# MK22F12810 register map
Vendor: Freescale Semiconductor, Inc.; Series: Kinetis_K; File version: 1.6
CPU: CM4 r0p1, little endian, no MPU, FPU, VTOR, 4 interrupt priority bits
Registers are 32-bit, read-write, reset 0x0 unless marked. A register's access mark holds for its fields unless they carry their own. Offsets are from the block's base; [hi:lo] are bit positions; {n}, {i} and the like mark numbered series.

## USB0 — Universal Serial Bus, OTG Capable Controller
Base 0x40072000; register names take the prefix USB0_
0x00 PERID 8-bit ro reset 0x4 — Peripheral ID register
  [5:0] ID — Peripheral Identification
0x04 IDCOMP 8-bit ro reset 0xFB — Peripheral ID Complement register
  [5:0] NID
0x08 REV 8-bit ro reset 0x33 — Peripheral Revision register
  [7:0] REV — Revision
0x0C ADDINFO 8-bit ro reset 0x1 — Peripheral Additional Info register
  [0] IEHOST
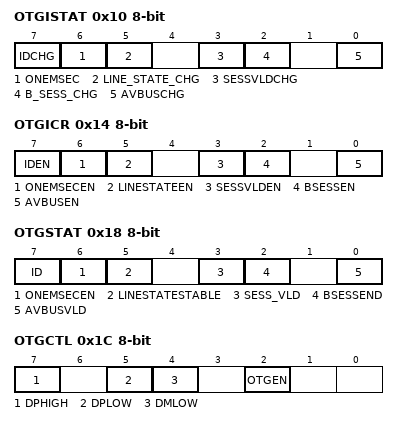
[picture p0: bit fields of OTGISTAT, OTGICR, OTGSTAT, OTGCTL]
0x10 OTGISTAT 8-bit — OTG Interrupt Status register
  [7] IDCHG, [6] ONEMSEC, [5] LINE_STATE_CHG, [3] SESSVLDCHG, [2] B_SESS_CHG, [0] AVBUSCHG
0x14 OTGICR 8-bit — OTG Interrupt Control register
  [7] IDEN — ID Interrupt Enable
    0=The ID interrupt is disabled; 1=The ID interrupt is enabled
  [6] ONEMSECEN — One Millisecond Interrupt Enable
    0=Diables the 1ms timer interrupt; 1=Enables the 1ms timer interrupt
  [5] LINESTATEEN — Line State Change Interrupt Enable
    0=Disables the LINE_STAT_CHG interrupt; 1=Enables the LINE_STAT_CHG interrupt
  [3] SESSVLDEN — Session Valid Interrupt Enable
    0=Disables the SESSVLDCHG interrupt; 1=Enables the SESSVLDCHG interrupt
  [2] BSESSEN — B Session END Interrupt Enable
    0=Disables the B_SESS_CHG interrupt; 1=Enables the B_SESS_CHG interrupt
  [0] AVBUSEN — A VBUS Valid Interrupt Enable
    0=Disables the AVBUSCHG interrupt; 1=Enables the AVBUSCHG interrupt
0x18 OTGSTAT 8-bit — OTG Status register
  [7] ID
    0=Indicates a Type A cable is plugged into the USB connector; 1=Indicates no cable is attached or a Type B cable is plugged into the USB connector
  [6] ONEMSECEN
  [5] LINESTATESTABLE
    0=The LINE_STAT_CHG bit is not yet stable; 1=The LINE_STAT_CHG bit has been debounced and is stable
  [3] SESS_VLD — Session Valid
    0=The VBUS voltage is below the B session valid threshold; 1=The VBUS voltage is above the B session valid threshold
  [2] BSESSEND — B Session End
    0=The VBUS voltage is above the B session end threshold; 1=The VBUS voltage is below the B session end threshold
  [0] AVBUSVLD — A VBUS Valid
    0=The VBUS voltage is below the A VBUS Valid threshold; 1=The VBUS voltage is above the A VBUS Valid threshold
0x1C OTGCTL 8-bit — OTG Control register
  [7] DPHIGH — D+ Data Line pullup resistor enable
    0=D+ pullup resistor is not enabled; 1=D+ pullup resistor is enabled
  [5] DPLOW — D+ Data Line pull-down resistor enable
    0=D+ pulldown resistor is not enabled; 1=D+ pulldown resistor is enabled
  [4] DMLOW — D- Data Line pull-down resistor enable
    0=D- pulldown resistor is not enabled; 1=D- pulldown resistor is enabled
  [2] OTGEN — On-The-Go pullup/pulldown resistor enable
    0=If USB_EN is 1 and HOST_MODE is 0 in the Control Register (CTL), then the D+ Data Line pull-up resistors are enabled. If HOST_MODE is 1 the D+ and D- Data Line pull-down resistors are engaged.; 1=The pull-up and pull-down controls in this register are used
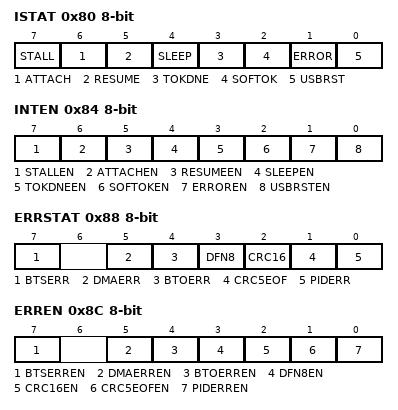
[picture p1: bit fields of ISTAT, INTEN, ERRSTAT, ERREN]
0x80 ISTAT 8-bit — Interrupt Status register
  [7] STALL — Stall Interrupt
  [6] ATTACH — Attach Interrupt
    0=No Attach is detected since the last time the ATTACH bit was cleared; 1=A peripheral is now present and must be configured (a stable non-SE0 state is detected for more than 2.5 us)
  [5] RESUME
  [4] SLEEP
  [3] TOKDNE
  [2] SOFTOK
  [1] ERROR
  [0] USBRST
0x84 INTEN 8-bit — Interrupt Enable register
  [7] STALLEN — STALL Interrupt Enable
    0=Diasbles the STALL interrupt; 1=Enables the STALL interrupt
  [6] ATTACHEN — ATTACH Interrupt Enable
    0=Disables the ATTACH interrupt; 1=Enables the ATTACH interrupt
  [5] RESUMEEN — RESUME Interrupt Enable
    0=Disables the RESUME interrupt; 1=Enables the RESUME interrupt
  [4] SLEEPEN — SLEEP Interrupt Enable
    0=Disables the SLEEP interrupt; 1=Enables the SLEEP interrupt
  [3] TOKDNEEN — TOKDNE Interrupt Enable
    0=Disables the TOKDNE interrupt; 1=Enables the TOKDNE interrupt
  [2] SOFTOKEN — SOFTOK Interrupt Enable
    0=Disbles the SOFTOK interrupt; 1=Enables the SOFTOK interrupt
  [1] ERROREN — ERROR Interrupt Enable
    0=Disables the ERROR interrupt; 1=Enables the ERROR interrupt
  [0] USBRSTEN — USBRST Interrupt Enable
    0=Disables the USBRST interrupt; 1=Enables the USBRST interrupt
0x88 ERRSTAT 8-bit — Error Interrupt Status register
  [7] BTSERR, [5] DMAERR, [4] BTOERR, [3] DFN8, [2] CRC16, [1] CRC5EOF, [0] PIDERR
0x8C ERREN 8-bit — Error Interrupt Enable register
  [7] BTSERREN — BTSERR Interrupt Enable
    0=Disables the BTSERR interrupt; 1=Enables the BTSERR interrupt
  [5] DMAERREN — DMAERR Interrupt Enable
    0=Disables the DMAERR interrupt; 1=Enables the DMAERR interrupt
  [4] BTOERREN — BTOERR Interrupt Enable
    0=Disables the BTOERR interrupt; 1=Enables the BTOERR interrupt
  [3] DFN8EN — DFN8 Interrupt Enable
    0=Disables the DFN8 interrupt; 1=Enables the DFN8 interrupt
  [2] CRC16EN — CRC16 Interrupt Enable
    0=Disables the CRC16 interrupt; 1=Enables the CRC16 interrupt
  [1] CRC5EOFEN — CRC5/EOF Interrupt Enable
    0=Disables the CRC5/EOF interrupt; 1=Enables the CRC5/EOF interrupt
  [0] PIDERREN — PIDERR Interrupt Enable
    0=Disables the PIDERR interrupt; 1=Enters the PIDERR interrupt
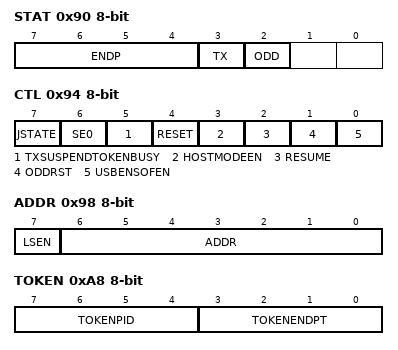
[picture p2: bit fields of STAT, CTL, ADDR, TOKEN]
0x90 STAT 8-bit ro — Status register
  [7:4] ENDP
  [3] TX — Transmit Indicator
    0=The most recent transaction was a receive operation; 1=The most recent transaction was a transmit operation
  [2] ODD
0x94 CTL 8-bit — Control register
  [7] JSTATE — Live USB differential receiver JSTATE signal
  [6] SE0 — Live USB Single Ended Zero signal
  [5] TXSUSPENDTOKENBUSY
  [4] RESET
  [3] HOSTMODEEN
  [2] RESUME
  [1] ODDRST
  [0] USBENSOFEN — USB Enable
    0=Disables the USB Module; 1=Enables the USB Module
0x98 ADDR 8-bit — Address register
  [7] LSEN — Low Speed Enable bit
  [6:0] ADDR — USB Address
0x9C BDTPAGE1 8-bit — BDT Page register 1
  [7:1] BDTBA
0xA0 FRMNUML 8-bit — Frame Number register Low
  [7:0] FRM
0xA4 FRMNUMH 8-bit — Frame Number register High
  [2:0] FRM
0xA8 TOKEN 8-bit
  [7:4] TOKENPID
    1=OUT Token. USB Module performs an OUT (TX) transaction.; 9=IN Token. USB Module performs an In (RX) transaction.; 13=SETUP Token. USB Module performs a SETUP (TX) transaction
  [3:0] TOKENENDPT
0xAC SOFTHLD 8-bit — SOF Threshold register
  [7:0] CNT
0xB0 BDTPAGE2 8-bit — BDT Page Register 2
  [7:0] BDTBA
0xB4 BDTPAGE3 8-bit — BDT Page Register 3
  [7:0] BDTBA
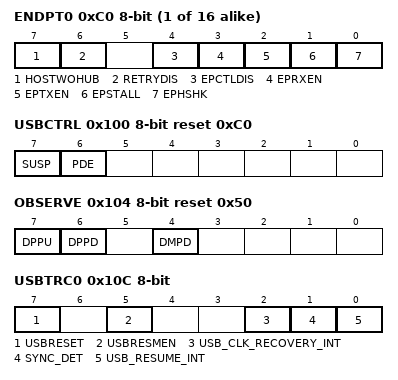
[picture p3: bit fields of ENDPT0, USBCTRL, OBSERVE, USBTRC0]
{0xC0+4i} ENDPT{i} (i=0..15) 8-bit — Endpoint Control register
  [7] HOSTWOHUB
    0=Low-speed device connected to Host through a hub. PRE_PID will be generated as required.; 1=Low-speed device directly connected. No hub, or no low-speed device attached.
  [6] RETRYDIS
  [4] EPCTLDIS
  [3] EPRXEN
  [2] EPTXEN
  [1] EPSTALL
  [0] EPHSHK
0x100 USBCTRL 8-bit reset 0xC0 — USB Control register
  [7] SUSP
    0=USB transceiver is not in suspend state; 1=USB transceiver is in suspend state
  [6] PDE
    0=Weak pulldowns are disabled on D+ and D-; 1=Weak pulldowns are enabled on D+ and D-
0x104 OBSERVE 8-bit ro reset 0x50 — USB OTG Observe register
  [7] DPPU
    0=D+ pullup disabled; 1=D+ pullup enabled
  [6] DPPD
    0=D+ pulldown disabled; 1=D+ pulldown enabled
  [4] DMPD
    0=D- pulldown disabled; 1=D- pulldown enabled
0x108 CONTROL 8-bit — USB OTG Control register
  [4] DPPULLUPNONOTG
    0=DP Pullup in non-OTG device mode is not enabled; 1=DP Pullup in non-OTG device mode is enabled
0x10C USBTRC0 8-bit — USB Transceiver Control register 0
  [7] USBRESET wo
    0=Normal USB module operation; 1=Returns the USB module to its reset state
  [5] USBRESMEN — Asynchronous Resume Interrupt Enable
    0=USB asynchronous wakeup from suspend mode disabled; 1=USB asynchronous wakeup from suspend mode enabled. The asynchronous resume interrupt differs from the synchronous resume interrupt in that it asynchronously detects K-state using the unfiltered state of the D+ and D- pins. This interrupt should only be enabled when the Transceiver is suspended.
  [2] USB_CLK_RECOVERY_INT ro — Combined USB Clock Recovery interrupt status
  [1] SYNC_DET ro — Synchronous USB Interrupt Detect
    0=Synchronous interrupt has not been detected; 1=Synchronous interrupt has been detected
  [0] USB_RESUME_INT ro — USB Asynchronous Interrupt
    0=No interrupt was generated; 1=Interrupt was generated because of the USB asynchronous interrupt
0x114 USBFRMADJUST 8-bit — Frame Adjust Register
  [7:0] ADJ — Frame Adjustment
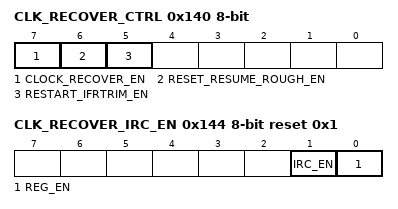
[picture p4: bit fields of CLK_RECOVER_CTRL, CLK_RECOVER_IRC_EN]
0x140 CLK_RECOVER_CTRL 8-bit — USB Clock recovery control
  [7] CLOCK_RECOVER_EN — Crystal-less USB enable
    0=Disable clock recovery block (default); 1=Enable clock recovery block
  [6] RESET_RESUME_ROUGH_EN — Reset/resume to rough phase enable
    0=Always works in tracking phase after the 1st time rough to track transition (default); 1=Go back to rough stage whenever bus reset or bus resume occurs
  [5] RESTART_IFRTRIM_EN — Restart from IFR trim value
    0=Trim fine adjustment always works based on the previous updated trim fine value (default); 1=Trim fine restarts from the IFR trim value whenever bus_reset/bus_resume is detected or module enable is desasserted
0x144 CLK_RECOVER_IRC_EN 8-bit reset 0x1 — IRC48M oscillator enable register
  [1] IRC_EN — IRC48M enable
    0=Disable the IRC48M module (default); 1=Enable the IRC48M module
  [0] REG_EN — IRC48M regulator enable
    0=IRC48M local regulator is disabled; 1=IRC48M local regulator is enabled (default)
0x154 CLK_RECOVER_INT_EN 8-bit reset 0x10 — Clock recovery combined interrupt enable
  [4] OVF_ERROR_EN
    0=The interrupt will be masked; 1=The interrupt will be enabled (default)
0x15C CLK_RECOVER_INT_STATUS 8-bit — Clock recovery separated interrupt status
  [4] OVF_ERROR
    0=No interrupt is reported; 1=Unmasked interrupt has been generated

## Notices in the file
Redistribution and use in source and binary forms, with or without modification,
are permitted provided that the following conditions are met:
o Redistributions of source code must retain the above copyright notice, this list
of conditions and the following disclaimer.
o Redistributions in binary form must reproduce the above copyright notice, this
list of conditions and the following disclaimer in the documentation and/or
other materials provided with the distribution.
o Neither the name of Freescale Semiconductor, Inc. nor the names of its
contributors may be used to endorse or promote products derived from this
software without specific prior written permission.
THIS SOFTWARE IS PROVIDED BY THE COPYRIGHT HOLDERS AND CONTRIBUTORS "AS IS" AND
ANY EXPRESS OR IMPLIED WARRANTIES, INCLUDING, BUT NOT LIMITED TO, THE IMPLIED
WARRANTIES OF MERCHANTABILITY AND FITNESS FOR A PARTICULAR PURPOSE ARE
DISCLAIMED. IN NO EVENT SHALL THE COPYRIGHT HOLDER OR CONTRIBUTORS BE LIABLE FOR
ANY DIRECT, INDIRECT, INCIDENTAL, SPECIAL, EXEMPLARY, OR CONSEQUENTIAL DAMAGES
(INCLUDING, BUT NOT LIMITED TO, PROCUREMENT OF SUBSTITUTE GOODS OR SERVICES;
LOSS OF USE, DATA, OR PROFITS; OR BUSINESS INTERRUPTION) HOWEVER CAUSED AND ON
ANY THEORY OF LIABILITY, WHETHER IN CONTRACT, STRICT LIABILITY, OR TORT
(INCLUDING NEGLIGENCE OR OTHERWISE) ARISING IN ANY WAY OUT OF THE USE OF THIS
SOFTWARE, EVEN IF ADVISED OF THE POSSIBILITY OF SUCH DAMAGE.
